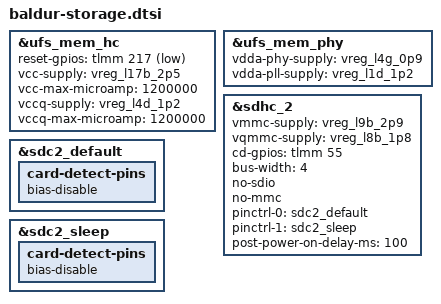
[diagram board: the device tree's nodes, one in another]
// SPDX-License-Identifier: BSD-3-Clause
/*
 * TB323FU ("baldur"): UFS and the microSD slot. Rails and GPIOs from this
 * device's ABL devicetree; they match the OnePlus 15 board DTS.
 *
 *	UFS    vcc      pmh0101 ldo17  2.504 V      (OnePlus: vreg_l17b_2p5)
 *	       vccq     pmh0110_d ldo4 1.2 V        (OnePlus: vreg_l4d_1p2)
 *	       reset    TLMM 217, active low        (OnePlus: the same GPIO)
 *	UFS    vdda-phy pmh0110_g ldo4 0.912 V      (OnePlus: vreg_l4g_0p9)
 *	PHY    vdda-pll pmh0110_d ldo1 1.2-1.256 V  (OnePlus: vreg_l1d_1p2)
 *	sdhc_2 vdd      pmh0101 ldo9   2.96-3.008 V (OnePlus: vreg_l9b_2p9)
 *	       vdd-io   pmh0101 ldo8   1.8-3.008 V  (OnePlus: vreg_l8b_1p8)
 *	       card det TLMM 55
 */


&ufs_mem_hc {
	reset-gpios = <&tlmm 217 GPIO_ACTIVE_LOW>;

	vcc-supply = <&vreg_l17b_2p5>;
	vcc-max-microamp = <1200000>;
	vccq-supply = <&vreg_l4d_1p2>;
	vccq-max-microamp = <1200000>;

	status = "okay";
};

&ufs_mem_phy {
	vdda-phy-supply = <&vreg_l4g_0p9>;
	vdda-pll-supply = <&vreg_l1d_1p2>;

	status = "okay";
};

/*
 * The microSD slot. Downstream says bus-width 4, no-sdio and no-mmc, and
 * drives the level shifter off vdd-io, which is why that rail spans 1.8 V to
 * 3.008 V rather than sitting at one voltage.
 *
 * Card detect is TLMM 55, active high as downstream has it.
 */
&sdhc_2 {
	vmmc-supply = <&vreg_l9b_2p9>;
	vqmmc-supply = <&vreg_l8b_1p8>;

	cd-gpios = <&tlmm 55 GPIO_ACTIVE_HIGH>;
	bus-width = <4>;
	no-sdio;
	no-mmc;

	pinctrl-0 = <&sdc2_default>;
	pinctrl-1 = <&sdc2_sleep>;
	pinctrl-names = "default", "sleep";

	/* the card needs about 45 ms between power-on and CMD8 */
	post-power-on-delay-ms = <100>;

	status = "okay";
};

/*
 * Card detect is active high with no pull: the SoC's SD states pull GPIO55
 * up for switches that pull it low.
 */
&sdc2_default {
	card-detect-pins {
		/delete-property/ bias-pull-up;
		bias-disable;
	};
};

&sdc2_sleep {
	card-detect-pins {
		/delete-property/ bias-pull-up;
		bias-disable;
	};
};
